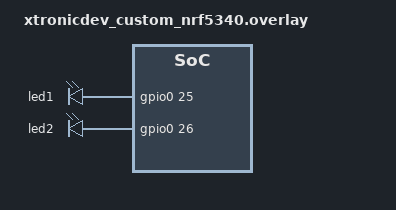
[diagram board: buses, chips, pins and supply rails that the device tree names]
// To get started, press Ctrl+Space to bring up the completion menu and view the available nodes.

// You can also use the buttons in the sidebar to perform actions on nodes.
// Actions currently available include:

// * Enabling / disabling the node
// * Adding the bus to a bus
// * Removing the node
// * Connecting ADC channels

// For more help, browse the DeviceTree documentation at https: //docs.zephyrproject.org/latest/guides/dts/index.html
// You can also visit the nRF DeviceTree extension documentation at https: //nrfconnect.github.io/vscode-nrf-connect/devicetree/nrfdevicetree.html

&gpio0 {
    status = "okay";
};

/ {
    gpio-leds {
        compatible = "gpio-leds";
        led1: led1 {
            gpios = <&gpio0 25 0>;
        };

        led2: led2 {
            gpios = <&gpio0 26 0>;
        };
    };
};
